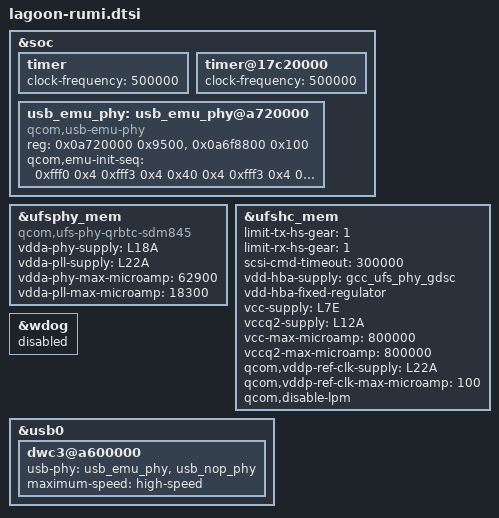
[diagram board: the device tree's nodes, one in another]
&soc {
	timer {
		clock-frequency = <500000>;
	};

	timer@17c20000 {
		clock-frequency = <500000>;
	};

	usb_emu_phy: usb_emu_phy@a720000 {
		compatible = "qcom,usb-emu-phy";
		reg = <0x0a720000 0x9500>,
		      <0x0a6f8800 0x100>;
		reg-names = "base", "qscratch_base";

		qcom,emu-init-seq = <0xfff0 0x4
				     0xfff3 0x4
				     0x40 0x4
				     0xfff3 0x4
				     0xfff0 0x4
				     0x100000 0x20
				     0x0 0x20
				     0x1a0 0x20
				     0x100000 0x3c
				     0x0 0x3c
				     0x10060 0x3c
				     0x0 0x4>;
	};

};

&ufsphy_mem {
	compatible = "qcom,ufs-phy-qrbtc-sdm845";

	vdda-phy-supply = <&L18A>;
	vdda-pll-supply = <&L22A>;
	vdda-phy-max-microamp = <62900>;
	vdda-pll-max-microamp = <18300>;

	status = "ok";
};

&ufshc_mem {
	limit-tx-hs-gear = <1>;
	limit-rx-hs-gear = <1>;
	scsi-cmd-timeout = <300000>;

	vdd-hba-supply = <&gcc_ufs_phy_gdsc>;
	vdd-hba-fixed-regulator;
	vcc-supply = <&L7E>;
	vccq2-supply = <&L12A>;
	vcc-max-microamp = <800000>;
	vccq2-max-microamp = <800000>;

	qcom,vddp-ref-clk-supply = <&L22A>;
	qcom,vddp-ref-clk-max-microamp = <100>;

	qcom,disable-lpm;
	status = "ok";
};

&wdog {
	status = "disabled";
};

&usb0 {
	dwc3@a600000 {
		usb-phy = <&usb_emu_phy>, <&usb_nop_phy>;
		maximum-speed = "high-speed";
	};
};
